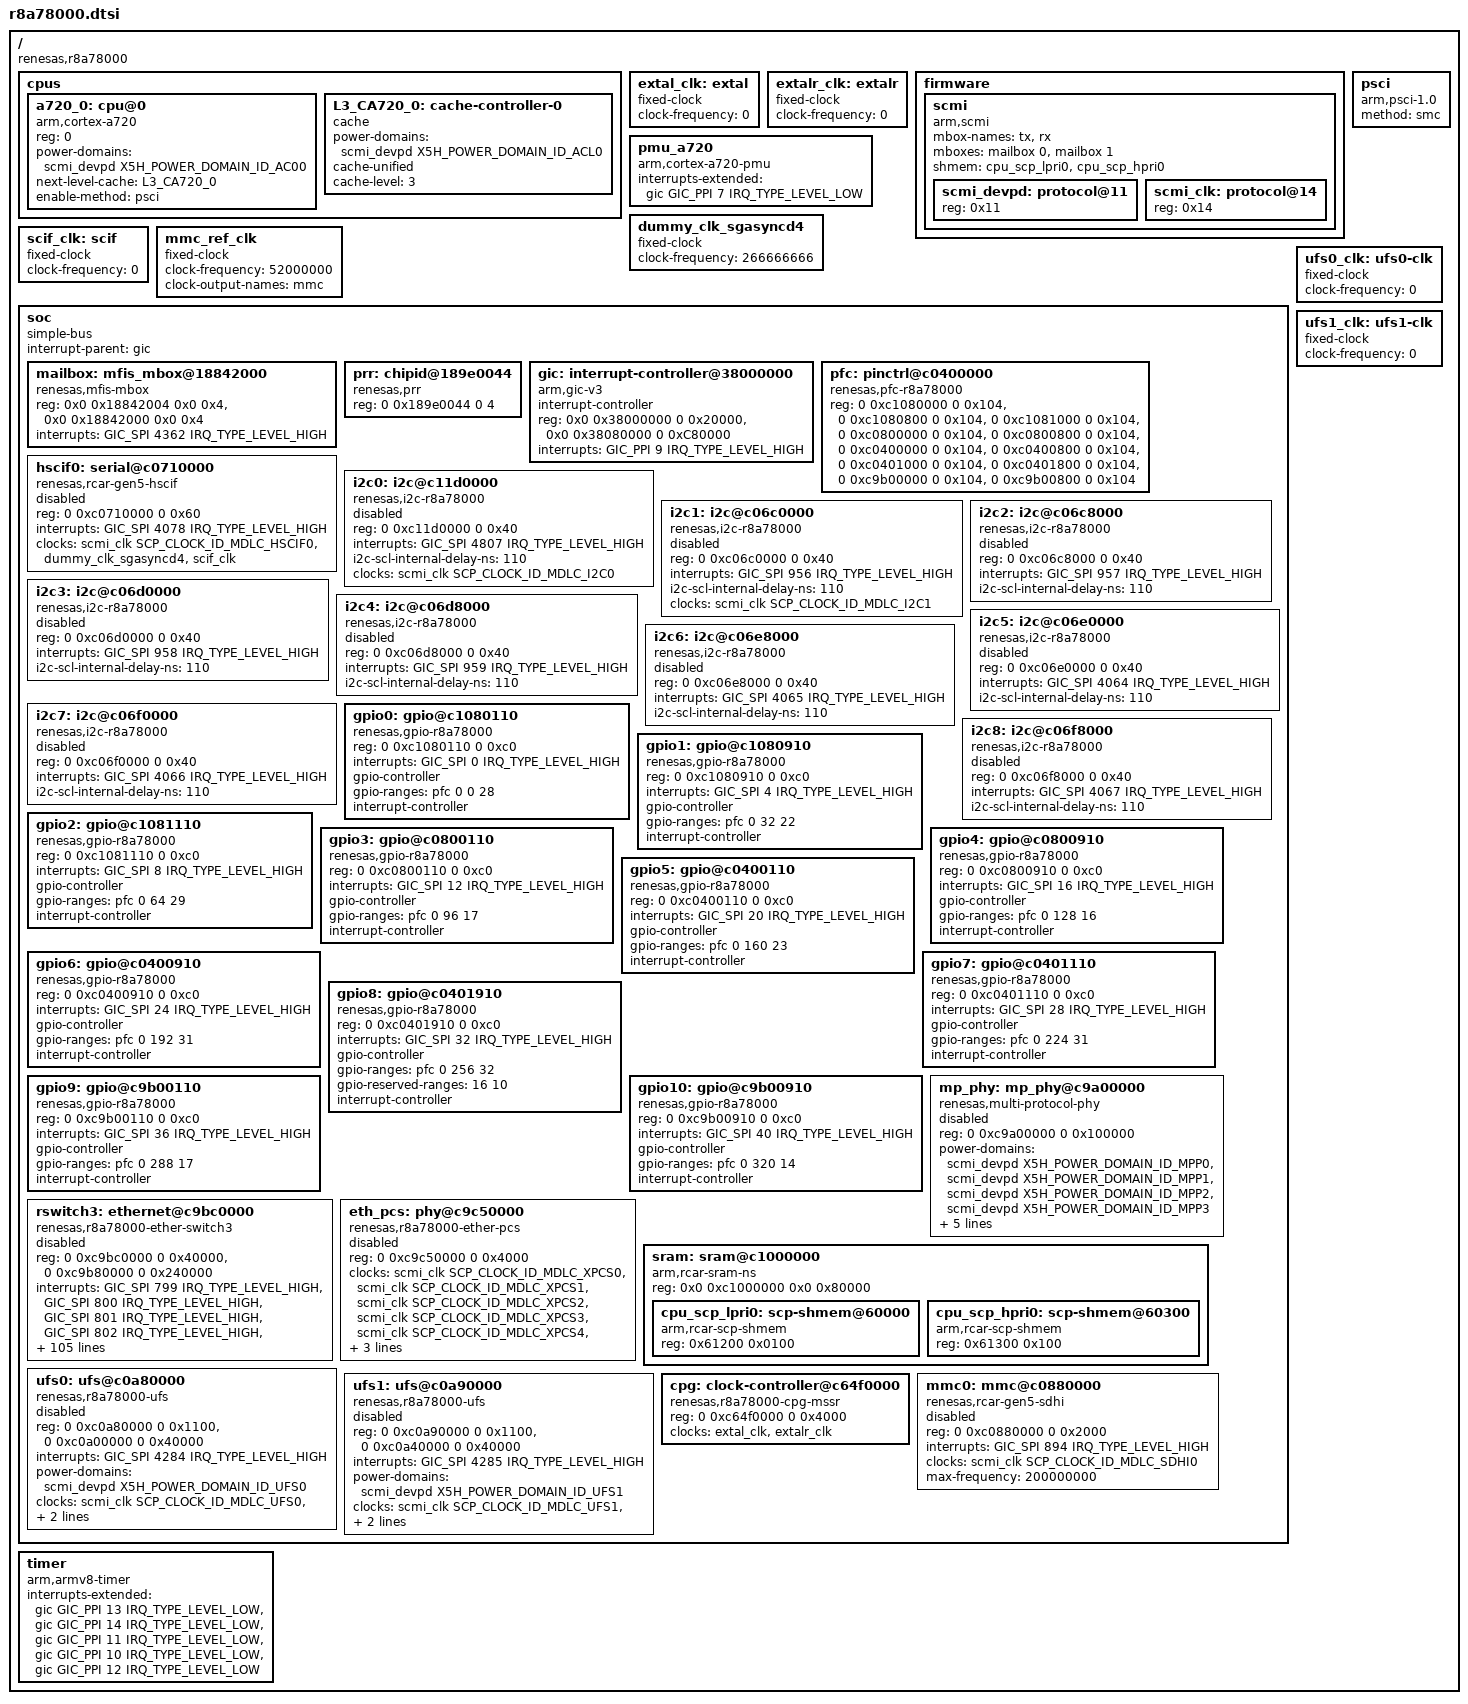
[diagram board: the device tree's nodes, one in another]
// SPDX-License-Identifier: (GPL-2.0-only OR BSD-2-Clause)
/*
 * Device Tree Source for the R-Car X5H (R8A78000) SoC
 *
 * Copyright (C) 2025 Renesas Electronics Corp.
 */

#include <dt-bindings/clock/r8a78000-scmi-clock.h>
#include <dt-bindings/clock/r8a78000-scmi-reset.h>
#include <dt-bindings/interrupt-controller/arm-gic.h>
#include <dt-bindings/power/r8a78000-scmi-power.h>

/ {
	compatible = "renesas,r8a78000";
	#address-cells = <2>;
	#size-cells = <2>;

	cpus {
		#address-cells = <1>;
		#size-cells = <0>;

		a720_0: cpu@0 {
			compatible = "arm,cortex-a720";
			reg = <0>;
			device_type = "cpu";
			power-domains = <&scmi_devpd X5H_POWER_DOMAIN_ID_AC00>;
			next-level-cache = <&L3_CA720_0>;
			enable-method = "psci";
		};

		L3_CA720_0: cache-controller-0 {
			compatible = "cache";
			power-domains = <&scmi_devpd X5H_POWER_DOMAIN_ID_ACL0>;
			cache-unified;
			cache-level = <3>;
		};
	};

	extal_clk: extal {
		compatible = "fixed-clock";
		#clock-cells = <0>;
		/* This value must be overridden by the board */
		clock-frequency = <0>;
	};

	extalr_clk: extalr {
		compatible = "fixed-clock";
		#clock-cells = <0>;
		/* This value must be overridden by the board */
		clock-frequency = <0>;
	};

	firmware {
		scmi {
			compatible = "arm,scmi";
			mbox-names = "tx","rx";
			mboxes = <&mailbox 0 &mailbox 1>;
			shmem = <&cpu_scp_lpri0 &cpu_scp_hpri0>;
			#address-cells = <1>;
			#size-cells = <0>;

			scmi_devpd: protocol@11 {
				reg = <0x11>;
				#power-domain-cells = <1>;
			};

			scmi_clk: protocol@14 {
				reg = <0x14>;
				#clock-cells = <1>;
			};

			/* TODO: scmi_reset */
		};
	};

	pmu_a720 {
		compatible = "arm,cortex-a720-pmu";
		interrupts-extended = <&gic GIC_PPI 7 IRQ_TYPE_LEVEL_LOW>;
	};

	psci {
		compatible = "arm,psci-1.0", "arm,psci-0.2";
		method = "smc";
	};

	/* In the early phase, there is no clock control support,
	 * so assume that the clocks are enabled by default.
	 * Therefore, dummy clocks are used.
	 */
	dummy_clk_sgasyncd4: dummy_clk_sgasyncd4 {
		compatible = "fixed-clock";
		#clock-cells = <0>;
		clock-frequency = <266666666>;
	};

	/* External SCIF clock - to be overridden by boards that provide it */
	scif_clk: scif {
		compatible = "fixed-clock";
		#clock-cells = <0>;
		clock-frequency = <0>;
	};

	mmc_ref_clk: mmc_ref_clk {
		compatible = "fixed-clock";
		#clock-cells = <0>;
		clock-frequency = <52000000>;
		clock-output-names = "mmc";
	};


	soc: soc {
		compatible = "simple-bus";
		interrupt-parent = <&gic>;
		#address-cells = <2>;
		#size-cells = <2>;
		ranges;

		mailbox: mfis_mbox@18842000 {
			compatible = "renesas,mfis-mbox";
			#mbox-cells = <1>;
			reg = <0x0 0x18842004 0x0 0x4>,
			      <0x0 0x18842000 0x0 0x4>;
			interrupts = <GIC_SPI 4362 IRQ_TYPE_LEVEL_HIGH>;
			status = "okay";
		};

		prr: chipid@189e0044 {
			compatible = "renesas,prr";
			reg = <0 0x189e0044 0 4>;
		};

		gic: interrupt-controller@38000000 {
			compatible = "arm,gic-v3";
			#interrupt-cells = <3>;
			#address-cells = <0>;
			interrupt-controller;
			reg = <0x0 0x38000000 0 0x20000>,
			      <0x0 0x38080000 0 0xC80000>;
			interrupts = <GIC_PPI 9 IRQ_TYPE_LEVEL_HIGH>;
		};

		pfc: pinctrl@c0400000 {
			compatible = "renesas,pfc-r8a78000";
			reg = <0 0xc1080000 0 0x104>, <0 0xc1080800 0 0x104>,
			<0 0xc1081000 0 0x104>, <0 0xc0800000 0 0x104>,
			<0 0xc0800800 0 0x104>, <0 0xc0400000 0 0x104>,
			<0 0xc0400800 0 0x104>, <0 0xc0401000 0 0x104>,
			<0 0xc0401800 0 0x104>, <0 0xc9b00000 0 0x104>,
			<0 0xc9b00800 0 0x104>;
		};

		hscif0: serial@c0710000 {
			compatible = "renesas,rcar-gen5-hscif", "renesas,hscif";
			reg = <0 0xc0710000 0 0x60>;
			interrupts = <GIC_SPI 4078 IRQ_TYPE_LEVEL_HIGH>;
			clocks = <&scmi_clk SCP_CLOCK_ID_MDLC_HSCIF0>,
				     <&dummy_clk_sgasyncd4>, <&scif_clk>;
			clock-names = "fck", "brg_int", "scif_clk";
			status = "disabled";
		};

		i2c0: i2c@c11d0000 {
			compatible = "renesas,i2c-r8a78000",
				     "renesas,rcar-gen5-i2c";
			reg = <0 0xc11d0000 0 0x40>;
			interrupts = <GIC_SPI 4807 IRQ_TYPE_LEVEL_HIGH>;
			i2c-scl-internal-delay-ns = <110>;
			clocks = <&scmi_clk SCP_CLOCK_ID_MDLC_I2C0>;
			#address-cells = <1>;
			#size-cells = <0>;
			status = "disabled";
		};

		i2c1: i2c@c06c0000 {
			compatible = "renesas,i2c-r8a78000",
				     "renesas,rcar-gen5-i2c";
			reg = <0 0xc06c0000 0 0x40>;
			interrupts = <GIC_SPI 956 IRQ_TYPE_LEVEL_HIGH>;
			i2c-scl-internal-delay-ns = <110>;
			clocks = <&scmi_clk SCP_CLOCK_ID_MDLC_I2C1>;
			#address-cells = <1>;
			#size-cells = <0>;
			status = "disabled";
		};

		i2c2: i2c@c06c8000 {
			compatible = "renesas,i2c-r8a78000",
				     "renesas,rcar-gen5-i2c";
			reg = <0 0xc06c8000 0 0x40>;
			interrupts = <GIC_SPI 957 IRQ_TYPE_LEVEL_HIGH>;
			i2c-scl-internal-delay-ns = <110>;
			#address-cells = <1>;
			#size-cells = <0>;
			status = "disabled";
		};

		i2c3: i2c@c06d0000 {
			compatible = "renesas,i2c-r8a78000",
				     "renesas,rcar-gen5-i2c";
			reg = <0 0xc06d0000 0 0x40>;
			interrupts = <GIC_SPI 958 IRQ_TYPE_LEVEL_HIGH>;
			i2c-scl-internal-delay-ns = <110>;
			#address-cells = <1>;
			#size-cells = <0>;
			status = "disabled";
		};

		i2c4: i2c@c06d8000 {
			compatible = "renesas,i2c-r8a78000",
				     "renesas,rcar-gen5-i2c";
			reg = <0 0xc06d8000 0 0x40>;
			interrupts = <GIC_SPI 959 IRQ_TYPE_LEVEL_HIGH>;
			i2c-scl-internal-delay-ns = <110>;
			#address-cells = <1>;
			#size-cells = <0>;
			status = "disabled";
		};

		i2c5: i2c@c06e0000 {
			compatible = "renesas,i2c-r8a78000",
				     "renesas,rcar-gen5-i2c";
			reg = <0 0xc06e0000 0 0x40>;
			interrupts = <GIC_SPI 4064 IRQ_TYPE_LEVEL_HIGH>;
			i2c-scl-internal-delay-ns = <110>;
			#address-cells = <1>;
			#size-cells = <0>;
			status = "disabled";
		};

		i2c6: i2c@c06e8000 {
			compatible = "renesas,i2c-r8a78000",
				     "renesas,rcar-gen5-i2c";
			reg = <0 0xc06e8000 0 0x40>;
			interrupts = <GIC_SPI 4065 IRQ_TYPE_LEVEL_HIGH>;
			i2c-scl-internal-delay-ns = <110>;
			#address-cells = <1>;
			#size-cells = <0>;
			status = "disabled";
		};

		i2c7: i2c@c06f0000 {
			compatible = "renesas,i2c-r8a78000",
				     "renesas,rcar-gen5-i2c";
			reg = <0 0xc06f0000 0 0x40>;
			interrupts = <GIC_SPI 4066 IRQ_TYPE_LEVEL_HIGH>;
			i2c-scl-internal-delay-ns = <110>;
			#address-cells = <1>;
			#size-cells = <0>;
			status = "disabled";
		};

		i2c8: i2c@c06f8000 {
			compatible = "renesas,i2c-r8a78000",
				     "renesas,rcar-gen5-i2c";
			reg = <0 0xc06f8000 0 0x40>;
			interrupts = <GIC_SPI 4067 IRQ_TYPE_LEVEL_HIGH>;
			i2c-scl-internal-delay-ns = <110>;
			#address-cells = <1>;
			#size-cells = <0>;
			status = "disabled";
		};

		gpio0: gpio@c1080110 {
			compatible = "renesas,gpio-r8a78000",
				     "renesas,rcar-gen5-gpio";
			reg = <0 0xc1080110 0 0xc0>;
			interrupts = <GIC_SPI 0 IRQ_TYPE_LEVEL_HIGH>;
			#gpio-cells = <2>;
			gpio-controller;
			gpio-ranges = <&pfc 0 0 28>;
			#interrupt-cells = <2>;
			interrupt-controller;
		};

		gpio1: gpio@c1080910 {
			compatible = "renesas,gpio-r8a78000",
				     "renesas,rcar-gen5-gpio";
			reg = <0 0xc1080910 0 0xc0>;
			interrupts = <GIC_SPI 4 IRQ_TYPE_LEVEL_HIGH>;
			#gpio-cells = <2>;
			gpio-controller;
			gpio-ranges = <&pfc 0 32 22>;
			#interrupt-cells = <2>;
			interrupt-controller;
		};

		gpio2: gpio@c1081110 {
			compatible = "renesas,gpio-r8a78000",
				     "renesas,rcar-gen5-gpio";
			reg = <0 0xc1081110 0 0xc0>;
			interrupts = <GIC_SPI 8 IRQ_TYPE_LEVEL_HIGH>;
			#gpio-cells = <2>;
			gpio-controller;
			gpio-ranges = <&pfc 0 64 29>;
			#interrupt-cells = <2>;
			interrupt-controller;
		};

		gpio3: gpio@c0800110 {
			compatible = "renesas,gpio-r8a78000",
				     "renesas,rcar-gen5-gpio";
			reg = <0 0xc0800110 0 0xc0>;
			interrupts = <GIC_SPI 12 IRQ_TYPE_LEVEL_HIGH>;
			#gpio-cells = <2>;
			gpio-controller;
			gpio-ranges = <&pfc 0 96 17>;
			#interrupt-cells = <2>;
			interrupt-controller;
		};

		gpio4: gpio@c0800910 {
			compatible = "renesas,gpio-r8a78000",
				     "renesas,rcar-gen5-gpio";
			reg = <0 0xc0800910 0 0xc0>;
			interrupts = <GIC_SPI 16 IRQ_TYPE_LEVEL_HIGH>;
			#gpio-cells = <2>;
			gpio-controller;
			gpio-ranges = <&pfc 0 128 16>;
			#interrupt-cells = <2>;
			interrupt-controller;
		};

		gpio5: gpio@c0400110 {
			compatible = "renesas,gpio-r8a78000",
				     "renesas,rcar-gen5-gpio";
			reg = <0 0xc0400110 0 0xc0>;
			interrupts = <GIC_SPI 20 IRQ_TYPE_LEVEL_HIGH>;
			#gpio-cells = <2>;
			gpio-controller;
			gpio-ranges = <&pfc 0 160 23>;
			#interrupt-cells = <2>;
			interrupt-controller;
		};

		gpio6: gpio@c0400910 {
			compatible = "renesas,gpio-r8a78000",
				     "renesas,rcar-gen5-gpio";
			reg = <0 0xc0400910 0 0xc0>;
			interrupts = <GIC_SPI 24 IRQ_TYPE_LEVEL_HIGH>;
			#gpio-cells = <2>;
			gpio-controller;
			gpio-ranges = <&pfc 0 192 31>;
			#interrupt-cells = <2>;
			interrupt-controller;
		};

		gpio7: gpio@c0401110 {
			compatible = "renesas,gpio-r8a78000",
				     "renesas,rcar-gen5-gpio";
			reg = <0 0xc0401110 0 0xc0>;
			interrupts = <GIC_SPI 28 IRQ_TYPE_LEVEL_HIGH>;
			#gpio-cells = <2>;
			gpio-controller;
			gpio-ranges = <&pfc 0 224 31>;
			#interrupt-cells = <2>;
			interrupt-controller;
		};

		gpio8: gpio@c0401910 {
			compatible = "renesas,gpio-r8a78000",
				     "renesas,rcar-gen5-gpio";
			reg = <0 0xc0401910 0 0xc0>;
			interrupts = <GIC_SPI 32 IRQ_TYPE_LEVEL_HIGH>;
			#gpio-cells = <2>;
			gpio-controller;
			gpio-ranges = <&pfc 0 256 32>;
			gpio-reserved-ranges = <16 10>;
			#interrupt-cells = <2>;
			interrupt-controller;
		};

		gpio9: gpio@c9b00110 {
			compatible = "renesas,gpio-r8a78000",
				     "renesas,rcar-gen5-gpio";
			reg = <0 0xc9b00110 0 0xc0>;
			interrupts = <GIC_SPI 36 IRQ_TYPE_LEVEL_HIGH>;
			#gpio-cells = <2>;
			gpio-controller;
			gpio-ranges = <&pfc 0 288 17>;
			#interrupt-cells = <2>;
			interrupt-controller;
		};

		gpio10: gpio@c9b00910 {
			compatible = "renesas,gpio-r8a78000",
				     "renesas,rcar-gen5-gpio";
			reg = <0 0xc9b00910 0 0xc0>;
			interrupts = <GIC_SPI 40 IRQ_TYPE_LEVEL_HIGH>;
			#gpio-cells = <2>;
			gpio-controller;
			gpio-ranges = <&pfc 0 320 14>;
			#interrupt-cells = <2>;
			interrupt-controller;
		};

		mp_phy: mp_phy@c9a00000 {
			compatible = "renesas,multi-protocol-phy";
			reg = <0 0xc9a00000 0 0x100000>;
			#phy-cells = <2>;
			power-domains = <&scmi_devpd X5H_POWER_DOMAIN_ID_MPP0>,
							<&scmi_devpd X5H_POWER_DOMAIN_ID_MPP1>,
							<&scmi_devpd X5H_POWER_DOMAIN_ID_MPP2>,
							<&scmi_devpd X5H_POWER_DOMAIN_ID_MPP3>;
			clocks = <&scmi_clk SCP_CLOCK_ID_MDLC_MPPHY01>,
				     <&scmi_clk SCP_CLOCK_ID_MDLC_MPPHY11>,
				     <&scmi_clk SCP_CLOCK_ID_MDLC_MPPHY21>,
					 <&scmi_clk SCP_CLOCK_ID_MDLC_MPPHY31>,
					 <&scmi_clk SCP_CLOCK_ID_MDLC_MPPHY02>;
			clock-names = "mpphy01", "mpphy11", "mpphy21",
						  "mpphy31", "mpphy02";
			status = "disabled";
		};

		rswitch3: ethernet@c9bc0000 {
			compatible = "renesas,r8a78000-ether-switch3",
					"renesas,etherswitch";
			reg = <0 0xc9bc0000 0 0x40000>, <0 0xc9b80000 0 0x240000>;
			reg-names = "base", "secure_base";
			interrupts = <GIC_SPI 799 IRQ_TYPE_LEVEL_HIGH>,
					<GIC_SPI 800 IRQ_TYPE_LEVEL_HIGH>,
					<GIC_SPI 801 IRQ_TYPE_LEVEL_HIGH>,
					<GIC_SPI 802 IRQ_TYPE_LEVEL_HIGH>,
					<GIC_SPI 803 IRQ_TYPE_LEVEL_HIGH>,
					<GIC_SPI 804 IRQ_TYPE_LEVEL_HIGH>,
					<GIC_SPI 805 IRQ_TYPE_LEVEL_HIGH>,
					<GIC_SPI 806 IRQ_TYPE_LEVEL_HIGH>,
					<GIC_SPI 807 IRQ_TYPE_LEVEL_HIGH>,
					<GIC_SPI 808 IRQ_TYPE_LEVEL_HIGH>,
					<GIC_SPI 809 IRQ_TYPE_LEVEL_HIGH>,
					<GIC_SPI 810 IRQ_TYPE_LEVEL_HIGH>,
					<GIC_SPI 811 IRQ_TYPE_LEVEL_HIGH>,
					<GIC_SPI 812 IRQ_TYPE_LEVEL_HIGH>,
					<GIC_SPI 813 IRQ_TYPE_LEVEL_HIGH>,
					<GIC_SPI 814 IRQ_TYPE_LEVEL_HIGH>,
					<GIC_SPI 815 IRQ_TYPE_LEVEL_HIGH>,
					<GIC_SPI 816 IRQ_TYPE_LEVEL_HIGH>,
					<GIC_SPI 817 IRQ_TYPE_LEVEL_HIGH>,
					<GIC_SPI 818 IRQ_TYPE_LEVEL_HIGH>,
					<GIC_SPI 819 IRQ_TYPE_LEVEL_HIGH>,
					<GIC_SPI 820 IRQ_TYPE_LEVEL_HIGH>,
					<GIC_SPI 821 IRQ_TYPE_LEVEL_HIGH>,
					<GIC_SPI 822 IRQ_TYPE_LEVEL_HIGH>,
					<GIC_SPI 823 IRQ_TYPE_LEVEL_HIGH>,
					<GIC_SPI 824 IRQ_TYPE_LEVEL_HIGH>,
					<GIC_SPI 825 IRQ_TYPE_LEVEL_HIGH>,
					<GIC_SPI 826 IRQ_TYPE_LEVEL_HIGH>,
					<GIC_SPI 827 IRQ_TYPE_LEVEL_HIGH>,
					<GIC_SPI 828 IRQ_TYPE_LEVEL_HIGH>,
					<GIC_SPI 829 IRQ_TYPE_LEVEL_HIGH>,
					<GIC_SPI 830 IRQ_TYPE_LEVEL_HIGH>,
					<GIC_SPI 831 IRQ_TYPE_LEVEL_HIGH>,
					<GIC_SPI 832 IRQ_TYPE_LEVEL_HIGH>,
					<GIC_SPI 833 IRQ_TYPE_LEVEL_HIGH>,
					<GIC_SPI 834 IRQ_TYPE_LEVEL_HIGH>,
					<GIC_SPI 835 IRQ_TYPE_LEVEL_HIGH>,
					<GIC_SPI 836 IRQ_TYPE_LEVEL_HIGH>,
					<GIC_SPI 837 IRQ_TYPE_LEVEL_HIGH>,
					<GIC_SPI 838 IRQ_TYPE_LEVEL_HIGH>,
					<GIC_SPI 839 IRQ_TYPE_LEVEL_HIGH>,
					<GIC_SPI 840 IRQ_TYPE_LEVEL_HIGH>,
					<GIC_SPI 841 IRQ_TYPE_LEVEL_HIGH>,
					<GIC_SPI 842 IRQ_TYPE_LEVEL_HIGH>,
					<GIC_SPI 843 IRQ_TYPE_LEVEL_HIGH>,
					<GIC_SPI 844 IRQ_TYPE_LEVEL_HIGH>,
					<GIC_SPI 845 IRQ_TYPE_LEVEL_HIGH>,
					<GIC_SPI 846 IRQ_TYPE_LEVEL_HIGH>,
					<GIC_SPI 847 IRQ_TYPE_LEVEL_HIGH>,
					<GIC_SPI 848 IRQ_TYPE_LEVEL_HIGH>,
					<GIC_SPI 849 IRQ_TYPE_LEVEL_HIGH>,
					<GIC_SPI 850 IRQ_TYPE_LEVEL_HIGH>,
					<GIC_SPI 851 IRQ_TYPE_LEVEL_HIGH>,
					<GIC_SPI 852 IRQ_TYPE_LEVEL_HIGH>,
					<GIC_SPI 853 IRQ_TYPE_LEVEL_HIGH>,
					<GIC_SPI 854 IRQ_TYPE_LEVEL_HIGH>,
					<GIC_SPI 855 IRQ_TYPE_LEVEL_HIGH>,
					<GIC_SPI 856 IRQ_TYPE_LEVEL_HIGH>,
					<GIC_SPI 857 IRQ_TYPE_LEVEL_HIGH>,
					<GIC_SPI 858 IRQ_TYPE_LEVEL_HIGH>,
					<GIC_SPI 859 IRQ_TYPE_LEVEL_HIGH>,
					<GIC_SPI 860 IRQ_TYPE_LEVEL_HIGH>,
					<GIC_SPI 861 IRQ_TYPE_LEVEL_HIGH>,
					<GIC_SPI 862 IRQ_TYPE_LEVEL_HIGH>,
					<GIC_SPI 863 IRQ_TYPE_LEVEL_HIGH>,
					<GIC_SPI 864 IRQ_TYPE_LEVEL_HIGH>,
					<GIC_SPI 865 IRQ_TYPE_LEVEL_HIGH>,
					<GIC_SPI 866 IRQ_TYPE_LEVEL_HIGH>,
					<GIC_SPI 867 IRQ_TYPE_LEVEL_HIGH>,
					<GIC_SPI 868 IRQ_TYPE_LEVEL_HIGH>,
					<GIC_SPI 869 IRQ_TYPE_LEVEL_HIGH>,
					<GIC_SPI 870 IRQ_TYPE_LEVEL_HIGH>,
					<GIC_SPI 871 IRQ_TYPE_LEVEL_HIGH>,
					<GIC_SPI 872 IRQ_TYPE_LEVEL_HIGH>,
					<GIC_SPI 873 IRQ_TYPE_LEVEL_HIGH>,
					<GIC_SPI 874 IRQ_TYPE_LEVEL_HIGH>,
					<GIC_SPI 875 IRQ_TYPE_LEVEL_HIGH>,
					<GIC_SPI 876 IRQ_TYPE_LEVEL_HIGH>,
					<GIC_SPI 877 IRQ_TYPE_LEVEL_HIGH>,
					<GIC_SPI 878 IRQ_TYPE_LEVEL_HIGH>,
					<GIC_SPI 879 IRQ_TYPE_LEVEL_HIGH>,
					<GIC_SPI 880 IRQ_TYPE_LEVEL_HIGH>,
					<GIC_SPI 881 IRQ_TYPE_LEVEL_HIGH>,
					<GIC_SPI 882 IRQ_TYPE_LEVEL_HIGH>,
					<GIC_SPI 883 IRQ_TYPE_LEVEL_HIGH>,
					<GIC_SPI 884 IRQ_TYPE_LEVEL_HIGH>,
					<GIC_SPI 885 IRQ_TYPE_LEVEL_HIGH>,
					<GIC_SPI 886 IRQ_TYPE_LEVEL_HIGH>,
					<GIC_SPI 887 IRQ_TYPE_LEVEL_HIGH>,
					<GIC_SPI 888 IRQ_TYPE_LEVEL_HIGH>,
					<GIC_SPI 889 IRQ_TYPE_LEVEL_HIGH>,
					<GIC_SPI 890 IRQ_TYPE_LEVEL_HIGH>,
					<GIC_SPI 891 IRQ_TYPE_LEVEL_HIGH>,
					<GIC_SPI 892 IRQ_TYPE_LEVEL_HIGH>,
					<GIC_SPI 893 IRQ_TYPE_LEVEL_HIGH>;
			interrupt-names = "race_wrap_mfwd_int", "race_wrap_race_int",
					"race_wrap_coma_int", "race_wrap_gwca0_int",
					"race_wrap_gwca1_int", "race_wrap_etha0_int",
					"race_wrap_etha1_int", "race_wrap_etha2_int",
					"race_wrap_etha3_int", "race_wrap_etha4_int",
					"race_wrap_etha5_int", "race_wrap_etha6_int",
					"race_wrap_etha7_int", "race_wrap_etha8_int",
					"race_wrap_etha9_int", "race_wrap_etha10_int",
					"race_wrap_etha11_int", "race_wrap_etha12_int",
					"race_wrap_gwca0_gwdis_int0", "race_wrap_gwca0_gwdis_int1",
					"race_wrap_gwca0_gwdis_int2", "race_wrap_gwca0_gwdis_int3",
					"race_wrap_gwca0_gwdis_int4", "race_wrap_gwca0_gwdis_int5",
					"race_wrap_gwca0_gwdis_int6", "race_wrap_gwca0_gwdis_int7",
					"gwca1_gwdis0", "gwca1_gwdis1",
					"gwca1_gwdis2", "gwca1_gwdis3",
					"gwca1_gwdis4", "gwca1_gwdis5",
					"gwca1_gwdis6", "gwca1_gwdis7",
					"race_wrap_gwca0_gwtsdis_int0", "race_wrap_gwca0_gwtsdis_int1",
					"race_wrap_gwca1_gwtsdis_int0", "race_wrap_gwca1_gwtsdis_int1",
					"race_wrap_gptp_int", "tes0_status_int",
					"tes0_tx_int", "tes0_rx_int",
					"tes0_ts_int", "tes0_error_int",
					"tes1_status_int", "tes1_tx_int",
					"tes1_rx_int", "tes1_ts_int",
					"tes1_error_int", "tes2_status_int",
					"tes2_tx_int", "tes2_rx_int",
					"tes2_ts_int", "tes2_error_int",
					"tes3_status_int", "tes3_tx_int",
					"tes3_rx_int", "tes3_ts_int",
					"tes3_error_int", "tes4_status_int",
					"tes4_tx_int", "tes4_rx_int",
					"tes4_ts_int", "tes4_error_int",
					"tes5_status_int", "tes5_tx_int",
					"tes5_rx_int", "tes5_ts_int",
					"tes5_error_int", "tes6_status_int",
					"tes6_tx_int", "tes6_rx_int",
					"tes6_ts_int", "tes6_error_int",
					"tes7_status_int", "tes7_tx_int",
					"tes7_rx_int", "tes7_ts_int",
					"tes7_error_int", "tes0_gptp_int",
					"tes1_gptp_int", "tes2_gptp_int",
					"tes3_gptp_int", "tes4_gptp_int",
					"tes5_gptp_int", "tes6_gptp_int",
					"tes7_gptp_int", "race_wrap_msc0_error_int",
					"race_wrap_msc1_error_int", "race_wrap_msc2_error_int",
					"race_wrap_msc3_error_int", "race_wrap_msc4_error_int",
					"race_wrap_msc5_error_int", "race_wrap_msc6_error_int",
					"race_wrap_msc7_error_int";
			power-domains = <&scmi_devpd X5H_POWER_DOMAIN_ID_RSW>;
			clocks = <&scmi_clk SCP_CLOCK_ID_MDLC_RSW3>,
					 <&scmi_clk SCP_CLOCK_ID_MDLC_RSW3TSN>,
					 <&scmi_clk SCP_CLOCK_ID_MDLC_RSW3AES>,
				     <&scmi_clk SCP_CLOCK_ID_MDLC_RSW3TSNTES0>,
				     <&scmi_clk SCP_CLOCK_ID_MDLC_RSW3TSNTES1>,
				     <&scmi_clk SCP_CLOCK_ID_MDLC_RSW3TSNTES2>,
				     <&scmi_clk SCP_CLOCK_ID_MDLC_RSW3TSNTES3>,
				     <&scmi_clk SCP_CLOCK_ID_MDLC_RSW3TSNTES4>,
				     <&scmi_clk SCP_CLOCK_ID_MDLC_RSW3TSNTES5>,
				     <&scmi_clk SCP_CLOCK_ID_MDLC_RSW3TSNTES6>,
				     <&scmi_clk SCP_CLOCK_ID_MDLC_RSW3TSNTES7>,
				     <&scmi_clk SCP_CLOCK_ID_MDLC_RSW3MFWD>;
			clock-names = "rsw3", "rsw3tsn", "rsw3aes",
						  "rsw3tsntes0", "rsw3tsntes1", "rsw3tsntes2",
						  "rsw3tsntes3", "rsw3tsntes4", "rsw3tsntes5",
						  "rsw3tsntes6", "rsw3tsntes7", "rsw3mfwd";
			// resets = <&cpg xxxx>;
			status = "disabled";
		};

		eth_pcs: phy@c9c50000 {
			compatible = "renesas,r8a78000-ether-pcs";
			reg = <0 0xc9c50000 0 0x4000>;
			#phy-cells = <1>;
			clocks = <&scmi_clk SCP_CLOCK_ID_MDLC_XPCS0>,
				     <&scmi_clk SCP_CLOCK_ID_MDLC_XPCS1>,
					 <&scmi_clk SCP_CLOCK_ID_MDLC_XPCS2>,
					 <&scmi_clk SCP_CLOCK_ID_MDLC_XPCS3>,
					 <&scmi_clk SCP_CLOCK_ID_MDLC_XPCS4>,
					 <&scmi_clk SCP_CLOCK_ID_MDLC_XPCS5>,
					 <&scmi_clk SCP_CLOCK_ID_MDLC_XPCS6>,
					 <&scmi_clk SCP_CLOCK_ID_MDLC_XPCS7>;
			clock-names = "xpcs0", "xpcs1", "xpcs2", "xpcs3",
						  "xpcs4", "xpcs5", "xpcs6", "xpcs7";
			status = "disabled";
		};

		sram: sram@c1000000 {
			compatible = "arm,rcar-sram-ns", "mmio-sram";
			reg = <0x0 0xc1000000 0x0 0x80000>;

			#address-cells = <1>;
			#size-cells = <1>;
			ranges = <0 0x0 0xc1000000 0x80000>;

			cpu_scp_lpri0: scp-shmem@60000 {
				compatible = "arm,rcar-scp-shmem", "arm,scmi-shmem";
				reg = <0x61200 0x0100>;
			};

			cpu_scp_hpri0: scp-shmem@60300 {
				compatible = "arm,rcar-scp-shmem", "arm,scmi-shmem";
				reg = <0x61300 0x100>;
			};
		};

		ufs0: ufs@c0a80000 {
			compatible = "renesas,r8a78000-ufs", "renesas,rcar-gen5-ufs";
			reg = <0 0xc0a80000 0 0x1100>, <0 0xc0a00000 0 0x40000>;
			reg-names = "hcr", "phy";
			interrupts = <GIC_SPI 4284 IRQ_TYPE_LEVEL_HIGH>;
			power-domains = <&scmi_devpd X5H_POWER_DOMAIN_ID_UFS0>;
			clocks = <&scmi_clk SCP_CLOCK_ID_MDLC_UFS0>, <&ufs0_clk>;
			clock-names = "ufs0", "ref_clk";
			freq-table-hz = <38400000 38400000>;
			status = "disabled";
		};

		ufs1: ufs@c0a90000 {
			compatible = "renesas,r8a78000-ufs", "renesas,rcar-gen5-ufs";
			reg = <0 0xc0a90000 0 0x1100>, <0 0xc0a40000 0 0x40000>;
			reg-names = "hcr", "phy";
			interrupts = <GIC_SPI 4285 IRQ_TYPE_LEVEL_HIGH>;
			power-domains = <&scmi_devpd X5H_POWER_DOMAIN_ID_UFS1>;
			clocks = <&scmi_clk SCP_CLOCK_ID_MDLC_UFS1>, <&ufs1_clk>;
			clock-names = "ufs1", "ref_clk";
			freq-table-hz = <38400000 38400000>;
			status = "disabled";
		};

		cpg: clock-controller@c64f0000 {
			compatible = "renesas,r8a78000-cpg-mssr";
			reg = <0 0xc64f0000 0 0x4000>;
			clocks = <&extal_clk>, <&extalr_clk>;
			clock-names = "extal", "extalr";
			#clock-cells = <2>;
			#power-domain-cells = <0>;
			#reset-cells = <1>;
		};

		mmc0: mmc@c0880000 {
			compatible = "renesas,rcar-gen5-sdhi";
			reg = <0 0xc0880000 0 0x2000>;
			interrupts = <GIC_SPI 894 IRQ_TYPE_LEVEL_HIGH>;
			//clocks = <&mmc_ref_clk>;
			clocks = <&scmi_clk SCP_CLOCK_ID_MDLC_SDHI0>;
			clock-names = "core";
			max-frequency = <200000000>;
			status = "disabled";
		};
	};

	timer {
		compatible = "arm,armv8-timer";
		interrupts-extended = <&gic GIC_PPI 13 IRQ_TYPE_LEVEL_LOW>,
				      <&gic GIC_PPI 14 IRQ_TYPE_LEVEL_LOW>,
				      <&gic GIC_PPI 11 IRQ_TYPE_LEVEL_LOW>,
				      <&gic GIC_PPI 10 IRQ_TYPE_LEVEL_LOW>,
				      <&gic GIC_PPI 12 IRQ_TYPE_LEVEL_LOW>;
		interrupt-names = "sec-phys", "phys", "virt", "hyp-phys",
				  "hyp-virt";
	};

	ufs0_clk: ufs0-clk {
		compatible = "fixed-clock";
		#clock-cells = <0>;
		/* This value must be overridden by the board */
		clock-frequency = <0>;
	};

	ufs1_clk: ufs1-clk {
		compatible = "fixed-clock";
		#clock-cells = <0>;
		/* This value must be overridden by the board */
		clock-frequency = <0>;
	};
};
